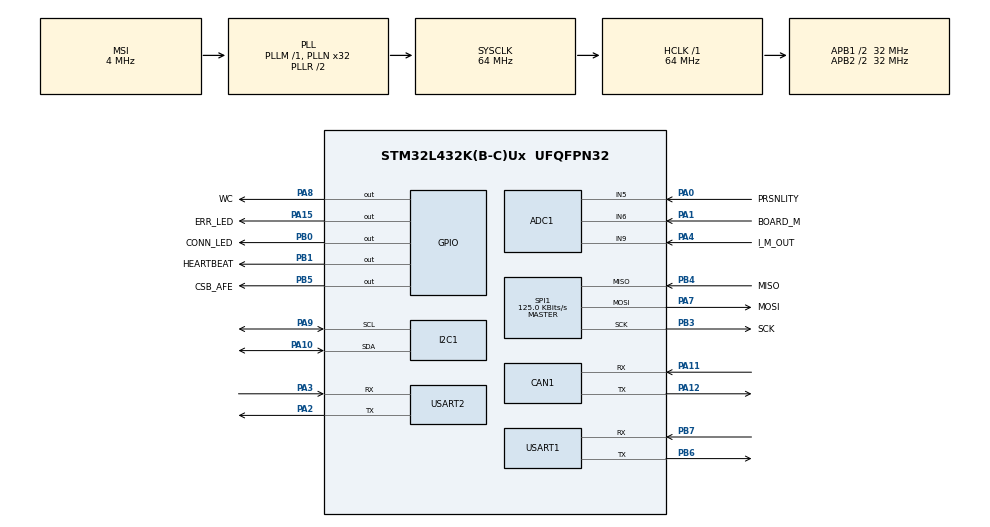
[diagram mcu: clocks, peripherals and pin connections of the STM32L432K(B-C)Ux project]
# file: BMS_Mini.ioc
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ADC1.Channel-0\#ChannelRegularConversion=ADC_CHANNEL_6
ADC1.NbrOfConversionFlag=1
ADC1.OffsetNumber-0\#ChannelRegularConversion=ADC_OFFSET_NONE
ADC1.Rank-0\#ChannelRegularConversion=1
ADC1.SamplingTime-0\#ChannelRegularConversion=ADC_SAMPLETIME_2CYCLES_5
ADC1.master=1
CAN1.BS1=CAN_BS1_5TQ
CAN1.CalculateTimeQuantum=500.0
I2C1.Timing=0x00707CBB
Mcu.Family=STM32L4
Mcu.Name=STM32L432K(B-C)Ux
Mcu.Package=UFQFPN32
NVIC.PriorityGroup=NVIC_PRIORITYGROUP_4
PA0.GPIO_Label=PRSNLITY
PA0.Signal=ADCx_IN5
PA1.GPIO_Label=BOARD_M
PA1.Signal=ADCx_IN6
PA10.Mode=I2C
PA10.Signal=I2C1_SDA
PA11.Mode=Master
PA11.Signal=CAN1_RX
PA12.Mode=Master
PA12.Signal=CAN1_TX
PA13\ (JTMS-SWDIO).Mode=Serial_Wire
PA13\ (JTMS-SWDIO).Signal=SYS_JTMS-SWDIO
PA14\ (JTCK-SWCLK).Mode=Serial_Wire
PA14\ (JTCK-SWCLK).Signal=SYS_JTCK-SWCLK
PA15\ (JTDI).GPIO_Label=ERR_LED
PA15\ (JTDI).Signal=GPIO_Output
PA2.Mode=Asynchronous
PA2.Signal=USART2_TX
PA3.Mode=Asynchronous
PA3.Signal=USART2_RX
PA4.GPIO_Label=I_M_OUT
PA4.Signal=ADCx_IN9
PA7.GPIO_Label=MOSI
PA7.Mode=Full_Duplex_Master
PA7.Signal=SPI1_MOSI
PA8.GPIO_Label=WC
PA8.Signal=GPIO_Output
PA9.Mode=I2C
PA9.Signal=I2C1_SCL
PB0.GPIO_Label=CONN_LED
PB0.Signal=GPIO_Output
PB1.GPIO_Label=HEARTBEAT
PB1.Signal=GPIO_Output
PB3\ (JTDO-TRACESWO).GPIO_Label=SCK
PB3\ (JTDO-TRACESWO).Mode=Full_Duplex_Master
PB3\ (JTDO-TRACESWO).Signal=SPI1_SCK
PB4\ (NJTRST).GPIO_Label=MISO
PB4\ (NJTRST).Mode=Full_Duplex_Master
PB4\ (NJTRST).Signal=SPI1_MISO
PB5.GPIO_Label=CSB_AFE
PB5.Signal=GPIO_Output
PB6.Mode=Asynchronous
PB6.Signal=USART1_TX
PB7.Mode=Asynchronous
PB7.Signal=USART1_RX
ProjectManager.HeapSize=0x200
ProjectManager.StackSize=0x400
ProjectManager.TargetToolchain=SW4STM32
RCC.ADCFreq_Value=32000000
RCC.AHBFreq_Value=64000000
RCC.APB1CLKDivider=RCC_HCLK_DIV2
RCC.APB1Freq_Value=32000000
RCC.APB1TimFreq_Value=64000000
RCC.APB2CLKDivider=RCC_HCLK_DIV2
RCC.APB2Freq_Value=32000000
RCC.APB2TimFreq_Value=64000000
RCC.CortexFreq_Value=64000000
RCC.HCLKFreq_Value=64000000
RCC.HSE_VALUE=8000000
RCC.HSI48_VALUE=48000000
RCC.HSI_VALUE=16000000
RCC.LSE_VALUE=32768
RCC.MSI_VALUE=4000000
RCC.PLLN=32
RCC.PLLSAI1N=16
RCC.SYSCLKFreq_VALUE=64000000
RCC.SYSCLKSource=RCC_SYSCLKSOURCE_PLLCLK
RCC.USBFreq_Value=32000000
RCC.VCOOutputFreq_Value=128000000
SH.ADCx_IN5.0=ADC1_IN5,IN5-Single-Ended
SH.ADCx_IN6.0=ADC1_IN6,IN6-Single-Ended
SH.ADCx_IN9.0=ADC1_IN9,IN9-Single-Ended
SPI1.BaudRatePrescaler=SPI_BAUDRATEPRESCALER_256
SPI1.CLKPhase=SPI_PHASE_2EDGE
SPI1.CLKPolarity=SPI_POLARITY_HIGH
SPI1.CalculateBaudRate=125.0 KBits/s
SPI1.DataSize=SPI_DATASIZE_8BIT
SPI1.Direction=SPI_DIRECTION_2LINES
SPI1.Mode=SPI_MODE_MASTER
SPI1.VirtualType=VM_MASTER
USART1.VirtualMode-Asynchronous=VM_ASYNC
USART2.VirtualMode-Asynchronous=VM_ASYNC
board=custom

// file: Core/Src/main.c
/* USER CODE BEGIN Header */
/**
  ******************************************************************************
  * @file           : main.c
  * @brief          : Main program body
  ******************************************************************************
  * @attention
  *
  * <h2><center>&copy; Copyright (c) 2021 STMicroelectronics.
  * All rights reserved.</center></h2>
  *
  * This software component is licensed by ST under BSD 3-Clause license,
  * the "License"; You may not use this file except in compliance with the
  * License. You may obtain a copy of the License at:
  *                        opensource.org/licenses/BSD-3-Clause
  *
  ******************************************************************************
  */
/* USER CODE END Header */
#include "main.h"

ADC_HandleTypeDef hadc1;

CAN_HandleTypeDef hcan1;

I2C_HandleTypeDef hi2c1;

SPI_HandleTypeDef hspi1;

UART_HandleTypeDef huart1;
UART_HandleTypeDef huart2;

void SystemClock_Config(void);
static void MX_GPIO_Init(void);
static void MX_ADC1_Init(void);
static void MX_CAN1_Init(void);
static void MX_I2C1_Init(void);
static void MX_USART1_UART_Init(void);
static void MX_USART2_UART_Init(void);
static void MX_SPI1_Init(void);

int main(void)
{

  /* MCU Configuration--------------------------------------------------------*/

  /* Reset of all peripherals, Initializes the Flash interface and the Systick. */
  HAL_Init();

  /* Configure the system clock */
  SystemClock_Config();

  /* Initialize all configured peripherals */
  MX_GPIO_Init();
  MX_ADC1_Init();
  MX_CAN1_Init();
  MX_I2C1_Init();
  MX_USART1_UART_Init();
  MX_USART2_UART_Init();
  MX_SPI1_Init();
  /* USER CODE BEGIN 2 */
  HAL_Delay(1000);
  initBMS();
  /* USER CODE END 2 */

  /* Infinite loop */
  while (1)
  {

  }
}

void SystemClock_Config(void)
{
  RCC_OscInitTypeDef RCC_OscInitStruct = {0};
  RCC_ClkInitTypeDef RCC_ClkInitStruct = {0};
  RCC_PeriphCLKInitTypeDef PeriphClkInit = {0};

  /** Initializes the RCC Oscillators according to the specified parameters
  * in the RCC_OscInitTypeDef structure.
  */
  RCC_OscInitStruct.OscillatorType = RCC_OSCILLATORTYPE_MSI;
  RCC_OscInitStruct.MSIState = RCC_MSI_ON;
  RCC_OscInitStruct.MSICalibrationValue = 0;
  RCC_OscInitStruct.MSIClockRange = RCC_MSIRANGE_6;
  RCC_OscInitStruct.PLL.PLLState = RCC_PLL_ON;
  RCC_OscInitStruct.PLL.PLLSource = RCC_PLLSOURCE_MSI;
  RCC_OscInitStruct.PLL.PLLM = 1;
  RCC_OscInitStruct.PLL.PLLN = 32;
  RCC_OscInitStruct.PLL.PLLP = RCC_PLLP_DIV7;
  RCC_OscInitStruct.PLL.PLLQ = RCC_PLLQ_DIV2;
  RCC_OscInitStruct.PLL.PLLR = RCC_PLLR_DIV2;
  if (HAL_RCC_OscConfig(&RCC_OscInitStruct) != HAL_OK)
  {
    Error_Handler();
  }
  /** Initializes the CPU, AHB and APB buses clocks
  */
  RCC_ClkInitStruct.ClockType = RCC_CLOCKTYPE_HCLK|RCC_CLOCKTYPE_SYSCLK
                              |RCC_CLOCKTYPE_PCLK1|RCC_CLOCKTYPE_PCLK2;
  RCC_ClkInitStruct.SYSCLKSource = RCC_SYSCLKSOURCE_PLLCLK;
  RCC_ClkInitStruct.AHBCLKDivider = RCC_SYSCLK_DIV1;
  RCC_ClkInitStruct.APB1CLKDivider = RCC_HCLK_DIV2;
  RCC_ClkInitStruct.APB2CLKDivider = RCC_HCLK_DIV2;

  if (HAL_RCC_ClockConfig(&RCC_ClkInitStruct, FLASH_LATENCY_3) != HAL_OK)
  {
    Error_Handler();
  }
  PeriphClkInit.PeriphClockSelection = RCC_PERIPHCLK_USART1|RCC_PERIPHCLK_USART2
                              |RCC_PERIPHCLK_I2C1|RCC_PERIPHCLK_ADC;
  PeriphClkInit.Usart1ClockSelection = RCC_USART1CLKSOURCE_PCLK2;
  PeriphClkInit.Usart2ClockSelection = RCC_USART2CLKSOURCE_PCLK1;
  PeriphClkInit.I2c1ClockSelection = RCC_I2C1CLKSOURCE_PCLK1;
  PeriphClkInit.AdcClockSelection = RCC_ADCCLKSOURCE_PLLSAI1;
  PeriphClkInit.PLLSAI1.PLLSAI1Source = RCC_PLLSOURCE_MSI;
  PeriphClkInit.PLLSAI1.PLLSAI1M = 1;
  PeriphClkInit.PLLSAI1.PLLSAI1N = 16;
  PeriphClkInit.PLLSAI1.PLLSAI1P = RCC_PLLP_DIV7;
  PeriphClkInit.PLLSAI1.PLLSAI1Q = RCC_PLLQ_DIV2;
  PeriphClkInit.PLLSAI1.PLLSAI1R = RCC_PLLR_DIV2;
  PeriphClkInit.PLLSAI1.PLLSAI1ClockOut = RCC_PLLSAI1_ADC1CLK;
  if (HAL_RCCEx_PeriphCLKConfig(&PeriphClkInit) != HAL_OK)
  {
    Error_Handler();
  }
  /** Configure the main internal regulator output voltage
  */
  if (HAL_PWREx_ControlVoltageScaling(PWR_REGULATOR_VOLTAGE_SCALE1) != HAL_OK)
  {
    Error_Handler();
  }
}

static void MX_ADC1_Init(void)
{

  ADC_ChannelConfTypeDef sConfig = {0};

  /** Common config
  */
  hadc1.Instance = ADC1;
  hadc1.Init.ClockPrescaler = ADC_CLOCK_ASYNC_DIV1;
  hadc1.Init.Resolution = ADC_RESOLUTION_12B;
  hadc1.Init.DataAlign = ADC_DATAALIGN_RIGHT;
  hadc1.Init.ScanConvMode = ADC_SCAN_DISABLE;
  hadc1.Init.EOCSelection = ADC_EOC_SINGLE_CONV;
  hadc1.Init.LowPowerAutoWait = DISABLE;
  hadc1.Init.ContinuousConvMode = DISABLE;
  hadc1.Init.NbrOfConversion = 1;
  hadc1.Init.DiscontinuousConvMode = DISABLE;
  hadc1.Init.ExternalTrigConv = ADC_SOFTWARE_START;
  hadc1.Init.ExternalTrigConvEdge = ADC_EXTERNALTRIGCONVEDGE_NONE;
  hadc1.Init.DMAContinuousRequests = DISABLE;
  hadc1.Init.Overrun = ADC_OVR_DATA_PRESERVED;
  hadc1.Init.OversamplingMode = DISABLE;
  if (HAL_ADC_Init(&hadc1) != HAL_OK)
  {
    Error_Handler();
  }
  /** Configure Regular Channel
  */
  sConfig.Channel = ADC_CHANNEL_6;
  sConfig.Rank = ADC_REGULAR_RANK_1;
  sConfig.SamplingTime = ADC_SAMPLETIME_2CYCLES_5;
  sConfig.SingleDiff = ADC_SINGLE_ENDED;
  sConfig.OffsetNumber = ADC_OFFSET_NONE;
  sConfig.Offset = 0;
  if (HAL_ADC_ConfigChannel(&hadc1, &sConfig) != HAL_OK)
  {
    Error_Handler();
  }

}

static void MX_CAN1_Init(void)
{

  hcan1.Instance = CAN1;
  hcan1.Init.Prescaler = 16;
  hcan1.Init.Mode = CAN_MODE_NORMAL;
  hcan1.Init.SyncJumpWidth = CAN_SJW_1TQ;
  hcan1.Init.TimeSeg1 = CAN_BS1_5TQ;
  hcan1.Init.TimeSeg2 = CAN_BS2_1TQ;
  hcan1.Init.TimeTriggeredMode = DISABLE;
  hcan1.Init.AutoBusOff = DISABLE;
  hcan1.Init.AutoWakeUp = DISABLE;
  hcan1.Init.AutoRetransmission = DISABLE;
  hcan1.Init.ReceiveFifoLocked = DISABLE;
  hcan1.Init.TransmitFifoPriority = DISABLE;
  if (HAL_CAN_Init(&hcan1) != HAL_OK)
  {
    Error_Handler();
  }

}

static void MX_I2C1_Init(void)
{

  hi2c1.Instance = I2C1;
  hi2c1.Init.Timing = 0x00707CBB;
  hi2c1.Init.OwnAddress1 = 0;
  hi2c1.Init.AddressingMode = I2C_ADDRESSINGMODE_7BIT;
  hi2c1.Init.DualAddressMode = I2C_DUALADDRESS_DISABLE;
  hi2c1.Init.OwnAddress2 = 0;
  hi2c1.Init.OwnAddress2Masks = I2C_OA2_NOMASK;
  hi2c1.Init.GeneralCallMode = I2C_GENERALCALL_DISABLE;
  hi2c1.Init.NoStretchMode = I2C_NOSTRETCH_DISABLE;
  if (HAL_I2C_Init(&hi2c1) != HAL_OK)
  {
    Error_Handler();
  }
  /** Configure Analogue filter
  */
  if (HAL_I2CEx_ConfigAnalogFilter(&hi2c1, I2C_ANALOGFILTER_ENABLE) != HAL_OK)
  {
    Error_Handler();
  }
  /** Configure Digital filter
  */
  if (HAL_I2CEx_ConfigDigitalFilter(&hi2c1, 0) != HAL_OK)
  {
    Error_Handler();
  }

}

static void MX_SPI1_Init(void)
{

  /* SPI1 parameter configuration*/
  hspi1.Instance = SPI1;
  hspi1.Init.Mode = SPI_MODE_MASTER;
  hspi1.Init.Direction = SPI_DIRECTION_2LINES;
  hspi1.Init.DataSize = SPI_DATASIZE_8BIT;
  hspi1.Init.CLKPolarity = SPI_POLARITY_HIGH;
  hspi1.Init.CLKPhase = SPI_PHASE_2EDGE;
  hspi1.Init.NSS = SPI_NSS_SOFT;
  hspi1.Init.BaudRatePrescaler = SPI_BAUDRATEPRESCALER_256;
  hspi1.Init.FirstBit = SPI_FIRSTBIT_MSB;
  hspi1.Init.TIMode = SPI_TIMODE_DISABLE;
  hspi1.Init.CRCCalculation = SPI_CRCCALCULATION_DISABLE;
  hspi1.Init.CRCPolynomial = 7;
  hspi1.Init.CRCLength = SPI_CRC_LENGTH_DATASIZE;
  hspi1.Init.NSSPMode = SPI_NSS_PULSE_DISABLE;
  if (HAL_SPI_Init(&hspi1) != HAL_OK)
  {
    Error_Handler();
  }

}

static void MX_USART1_UART_Init(void)
{

  huart1.Instance = USART1;
  huart1.Init.BaudRate = 115200;
  huart1.Init.WordLength = UART_WORDLENGTH_8B;
  huart1.Init.StopBits = UART_STOPBITS_1;
  huart1.Init.Parity = UART_PARITY_NONE;
  huart1.Init.Mode = UART_MODE_TX_RX;
  huart1.Init.HwFlowCtl = UART_HWCONTROL_NONE;
  huart1.Init.OverSampling = UART_OVERSAMPLING_16;
  huart1.Init.OneBitSampling = UART_ONE_BIT_SAMPLE_DISABLE;
  huart1.AdvancedInit.AdvFeatureInit = UART_ADVFEATURE_NO_INIT;
  if (HAL_UART_Init(&huart1) != HAL_OK)
  {
    Error_Handler();
  }

}

static void MX_USART2_UART_Init(void)
{

  huart2.Instance = USART2;
  huart2.Init.BaudRate = 115200;
  huart2.Init.WordLength = UART_WORDLENGTH_8B;
  huart2.Init.StopBits = UART_STOPBITS_1;
  huart2.Init.Parity = UART_PARITY_NONE;
  huart2.Init.Mode = UART_MODE_TX_RX;
  huart2.Init.HwFlowCtl = UART_HWCONTROL_NONE;
  huart2.Init.OverSampling = UART_OVERSAMPLING_16;
  huart2.Init.OneBitSampling = UART_ONE_BIT_SAMPLE_DISABLE;
  huart2.AdvancedInit.AdvFeatureInit = UART_ADVFEATURE_NO_INIT;
  if (HAL_UART_Init(&huart2) != HAL_OK)
  {
    Error_Handler();
  }

}

static void MX_GPIO_Init(void)
{
  GPIO_InitTypeDef GPIO_InitStruct = {0};

  /* GPIO Ports Clock Enable */
  __HAL_RCC_GPIOA_CLK_ENABLE();
  __HAL_RCC_GPIOB_CLK_ENABLE();

  /*Configure GPIO pin Output Level */
  HAL_GPIO_WritePin(GPIOB, CONN_LED_Pin|HEARTBEAT_Pin|CSB_AFE_Pin, GPIO_PIN_RESET);

  /*Configure GPIO pin Output Level */
  HAL_GPIO_WritePin(GPIOA, WC_Pin|ERR_LED_Pin, GPIO_PIN_RESET);

  /*Configure GPIO pins : CONN_LED_Pin HEARTBEAT_Pin CSB_AFE_Pin */
  GPIO_InitStruct.Pin = CONN_LED_Pin|HEARTBEAT_Pin|CSB_AFE_Pin;
  GPIO_InitStruct.Mode = GPIO_MODE_OUTPUT_PP;
  GPIO_InitStruct.Pull = GPIO_NOPULL;
  GPIO_InitStruct.Speed = GPIO_SPEED_FREQ_LOW;
  HAL_GPIO_Init(GPIOB, &GPIO_InitStruct);

  /*Configure GPIO pins : WC_Pin ERR_LED_Pin */
  GPIO_InitStruct.Pin = WC_Pin|ERR_LED_Pin;
  GPIO_InitStruct.Mode = GPIO_MODE_OUTPUT_PP;
  GPIO_InitStruct.Pull = GPIO_NOPULL;
  GPIO_InitStruct.Speed = GPIO_SPEED_FREQ_LOW;
  HAL_GPIO_Init(GPIOA, &GPIO_InitStruct);

}

void Error_Handler(void)
{
}

/************************ (C) COPYRIGHT STMicroelectronics *****END OF FILE****/
